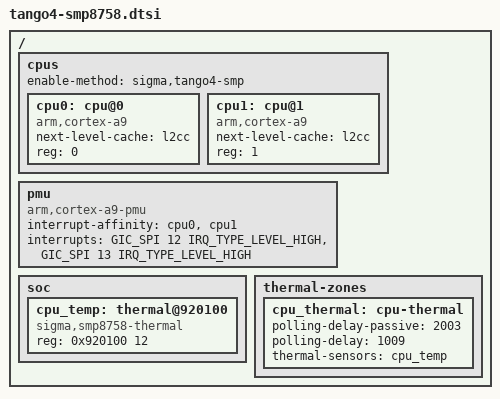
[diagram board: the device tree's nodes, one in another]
#include <dt-bindings/interrupt-controller/arm-gic.h>

/ {
	cpus {
		#address-cells = <1>;
		#size-cells = <0>;
		enable-method = "sigma,tango4-smp";

		cpu0: cpu@0 {
			compatible = "arm,cortex-a9";
			next-level-cache = <&l2cc>;
			device_type = "cpu";
			reg = <0>;
		};

		cpu1: cpu@1 {
			compatible = "arm,cortex-a9";
			next-level-cache = <&l2cc>;
			device_type = "cpu";
			reg = <1>;
		};
	};

	pmu {
		compatible = "arm,cortex-a9-pmu";
		interrupt-affinity = <&cpu0>, <&cpu1>;
		interrupts =
			<GIC_SPI 12 IRQ_TYPE_LEVEL_HIGH>,
			<GIC_SPI 13 IRQ_TYPE_LEVEL_HIGH>;
	};

	soc {
		cpu_temp: thermal@920100 {
			#thermal-sensor-cells = <0>;
			compatible = "sigma,smp8758-thermal";
			reg = <0x920100 12>;
		};
	};

	thermal-zones {
		cpu_thermal: cpu-thermal {
			polling-delay-passive = <2003>;	/* ms */
			polling-delay = <1009>;		/* ms */
			thermal-sensors = <&cpu_temp>;
		};
	};
};
